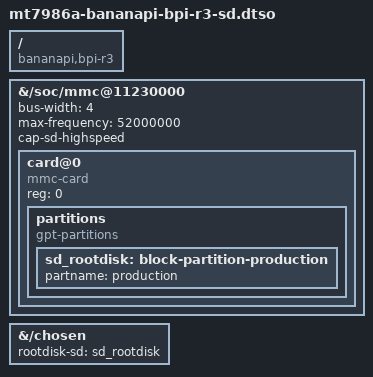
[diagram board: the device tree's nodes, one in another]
// SPDX-License-Identifier: (GPL-2.0 OR MIT)
/*
 * Copyright (C) 2021 MediaTek Inc.
 * Author: Sam.Shih <sam.shih@mediatek.com>
 */

/dts-v1/;
/plugin/;

/ {
	compatible = "bananapi,bpi-r3", "mediatek,mt7986a";
};

&{/soc/mmc@11230000} {
	bus-width = <4>;
	max-frequency = <52000000>;
	cap-sd-highspeed;
	#address-cells = <1>;
	#size-cells = <0>;
	status = "okay";

	card@0 {
		compatible = "mmc-card";
		reg = <0>;

		partitions {
			compatible = "gpt-partitions";

			sd_rootdisk: block-partition-production {
				partname = "production";
			};
		};
	};
};

&{/chosen} {
	rootdisk-sd = <&sd_rootdisk>;
};
